# PIC32CX1012BZ25048 device description
Architecture: CORTEX-M4; Family: PIC32CX; Series: BZ25
Registers are 32-bit, read-write, reset 0x0 unless marked. A register's access mark holds for its fields unless they carry their own. Offsets are from the block's base; [hi:lo] are bit positions; {n}, {i} and the like mark numbered series; <NAME> marks a mode.

## DMAC_DESCRIPTOR — Direct Memory Access Controller
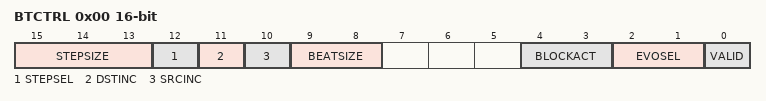
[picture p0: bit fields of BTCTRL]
0x00 BTCTRL 16-bit — Block Transfer Control
  [15:13] STEPSIZE — Address Increment Step Size
    0=Next ADDR = ADDR + (1<<BEATSIZE) * 1; 1=X2 (Next ADDR = ADDR + (1<<BEATSIZE) * 2); 2=X4 (Next ADDR = ADDR + (1<<BEATSIZE) * 4); 3=X8 (Next ADDR = ADDR + (1<<BEATSIZE) * 8); 4=X16 (Next ADDR = ADDR + (1<<BEATSIZE) * 16); 5=X32 (Next ADDR = ADDR + (1<<BEATSIZE) * 32); 6=X64 (Next ADDR = ADDR + (1<<BEATSIZE) * 64); 7=X128 (Next ADDR = ADDR + (1<<BEATSIZE) * 128)
  [12] STEPSEL — Step Selection
    0=DST (Step size settings apply to the destination address); 1=SRC (Step size settings apply to the source address)
  [11] DSTINC — Destination Address Increment Enable
  [10] SRCINC — Source Address Increment Enable
  [9:8] BEATSIZE
    0=BYTE (8-bit bus transfer); 1=HWORD (16-bit bus transfer); 2=WORD (32-bit bus transfer)
  [4:3] BLOCKACT — Block Action
    0=NOACT (Channel will be disabled if it is the last block transfer in the transaction); 1=INT (Channel will be disabled if it is the last block transfer in the transaction and block interrupt); 2=SUSPEND (Channel suspend operation is completed); 3=BOTH (Both channel suspend operation and block interrupt)
  [2:1] EVOSEL — Block Event Output Selection
    0=DISABLE (Event generation disabled); 1=BLOCK (Block event strobe); 3=BURST (Burst event strobe)
  [0] VALID — Descriptor Valid
0x02 BTCNT 16-bit — Block Transfer Count
0x04 SRCADDR — Block Transfer Source Address
  [31:0] SRCADDR — Transfer Source Address
0x08 DSTADDR reset not defined — Block Transfer Destination Address
  [31:0] CHKINIT <CRC> — CRC Checksum Initial Value
  [31:0] DSTADDR <DEFAULT> — Transfer Destination Address
0x0C DESCADDR reset not defined — Next Descriptor Address

## DMT — Dead Man Timer
Instances: DMT 0x44000E00
0x00 DMTCON
  [15] ON
0x04 DMTCONCLR — Bit clear register
0x08 DMTCONSET — Bit set register
0x0C DMTCONINV — Bit invert register
0x10 DMTPRECLR
  [15:8] STEP1
0x14 DMTPRECLRCLR — Bit clear register
0x18 DMTPRECLRSET — Bit set register
0x1C DMTPRECLRINV — Bit invert register
0x20 DMTCLR
  [7:0] STEP2
0x24 DMTCLRCLR — Bit clear register
0x28 DMTCLRSET — Bit set register
0x2C DMTCLRINV — Bit invert register
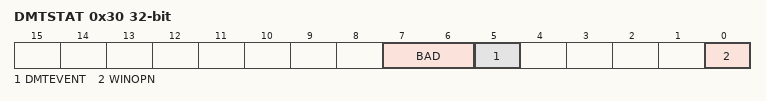
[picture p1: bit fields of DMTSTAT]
0x30 DMTSTAT
  [7:6] BAD, [5] DMTEVENT, [0] WINOPN
0x34 DMTSTATCLR — Bit clear register
0x38 DMTSTATSET — Bit set register
0x3C DMTSTATINV — Bit invert register
0x40 DMTCNT
  [31:0] COUNTER
0x44 DMTCNTCLR — Bit clear register
0x48 DMTCNTSET — Bit set register
0x4C DMTCNTINV — Bit invert register
0x50 DMTHOLDREG
  [15:0] UPRCNT
0x54 DMTHOLDREGCLR — Bit clear register
0x58 DMTHOLDREGSET — Bit set register
0x5C DMTHOLDREGINV — Bit invert register
0x60 DMTPSCNT
  [31:0] PSCNT
0x64 DMTPSCNTCLR — Bit clear register
0x68 DMTPSCNTSET — Bit set register
0x6C DMTPSCNTINV — Bit invert register
0x70 DMTPSINTV
  [31:0] PSINTV
0x74 DMTPSINTVCLR — Bit clear register
0x78 DMTPSINTVSET — Bit set register
0x7C DMTPSINTVINV — Bit invert register

## DSCON
Instances: DSCON 0x42011000
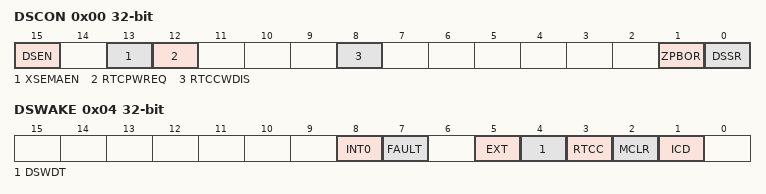
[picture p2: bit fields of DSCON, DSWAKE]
0x00 DSCON
  [15] DSEN, [13] XSEMAEN, [12] RTCPWREQ, [8] RTCCWDIS, [1] ZPBOR, [0] DSSR
0x04 DSWAKE
  [8] INT0, [7] FAULT, [5] EXT, [4] DSWDT, [3] RTCC, [2] MCLR, [1] ICD
0x08 DSSEMA1
  [31:0] DSSEMA
0x10 DSXSEMA1 reset not defined
  [31:0] DSXSEMA

## DSU — Device Service Unit
Instances: DSU 0x41000000
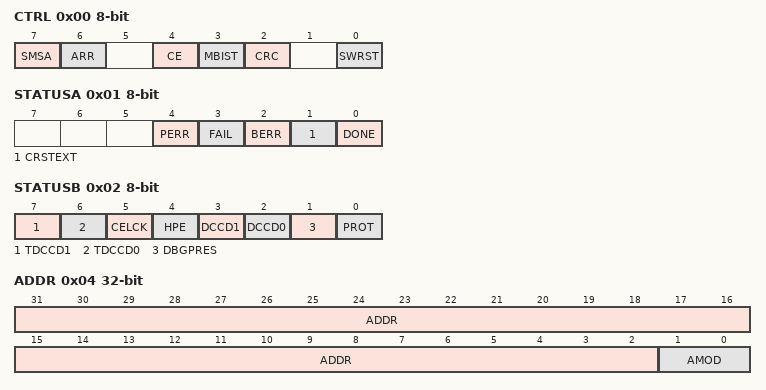
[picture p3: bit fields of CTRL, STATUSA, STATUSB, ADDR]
0x00 CTRL 8-bit wo — Control
  [7] SMSA — Start Memory Stream Access
  [6] ARR — Auxiliary Row Read
  [4] CE — Chip-Erase
  [3] MBIST — Memory built-in self-test
  [2] CRC — 32-bit Cyclic Redundancy Code
  [0] SWRST — Software Reset
0x01 STATUSA 8-bit
  [4] PERR — Protection Error
  [3] FAIL — Failure
  [2] BERR — Bus Error
  [1] CRSTEXT — CPU Reset Phase Extension
  [0] DONE
0x02 STATUSB 8-bit ro
  [7] TDCCD1 — Test Debug Communication Channel 1 Dirty
  [6] TDCCD0 — Test Debug Communication Channel 0 Dirty
  [5] CELCK — Chip Erase Locked
  [4] HPE — Hot-Plugging Enable
  [3] DCCD1 — Debug Communication Channel 1 Dirty
  [2] DCCD0 — Debug Communication Channel 0 Dirty
  [1] DBGPRES — Debugger Present
  [0] PROT — Protected
0x04 ADDR — Address
  [31:2] ADDR — Address
  [1:0] AMOD — Access Mode
0x08 LENGTH
  [31:2] LENGTH
0x0C DATA
{0x10+4i} DCC[{i}] (i=0..1) — Debug Communication Channel n
  [31:0] DATA
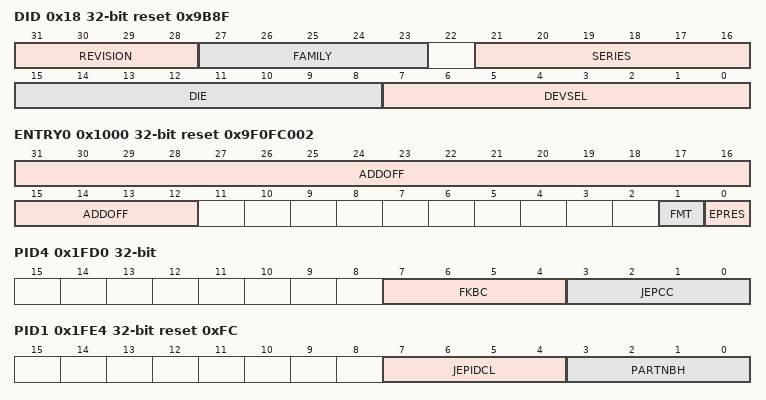
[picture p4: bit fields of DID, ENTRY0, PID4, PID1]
0x18 DID ro reset 0x9B8F — Device Identification
  [31:28] REVISION — Revision Number
  [27:23] FAMILY
    0=General purpose microcontroller; 1=PicoPower
  [21:16] SERIES
    0=Cortex-M0+ processor, basic feature set; 1=Cortex-M0+ processor, USB
  [15:8] DIE — Die Number
  [7:0] DEVSEL — Device Select
0x1000 ENTRY0 ro reset 0x9F0FC002 — CoreSight ROM Table Entry 0
  [31:12] ADDOFF — Address Offset
  [1] FMT — Format
  [0] EPRES — Entry Present
0x1004 ENTRY1 ro — CoreSight ROM Table Entry 1
0x1008 END ro — CoreSight ROM Table End
  [31:0] END — End Marker
0x1FCC MEMTYPE ro — CoreSight ROM Table Memory Type
  [0] SMEMP — System Memory Present
0x1FD0 PID4 ro — Peripheral Identification 4
  [7:4] FKBC — 4KB count
  [3:0] JEPCC — JEP-106 Continuation Code
0x1FE0 PID0 ro reset 0xD0 — Peripheral Identification 0
  [7:0] PARTNBL — Part Number Low
0x1FE4 PID1 ro reset 0xFC — Peripheral Identification 1
  [7:4] JEPIDCL — Low part of the JEP-106 Identity Code
  [3:0] PARTNBH — Part Number High
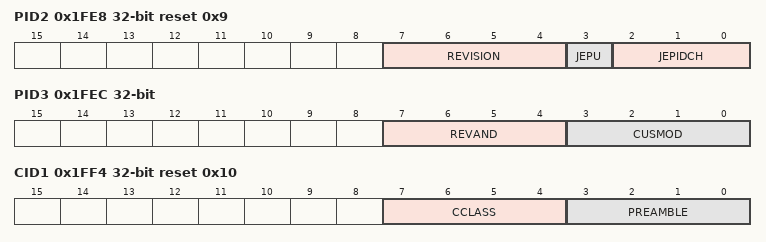
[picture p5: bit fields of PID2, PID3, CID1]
0x1FE8 PID2 ro reset 0x9 — Peripheral Identification 2
  [7:4] REVISION — Revision Number
  [3] JEPU — JEP-106 Identity Code is used
  [2:0] JEPIDCH — JEP-106 Identity Code High
0x1FEC PID3 ro — Peripheral Identification 3
  [7:4] REVAND — Revision Number
  [3:0] CUSMOD — ARM CUSMOD
0x1FF0 CID0 ro reset 0xD — Component Identification 0
  [7:0] PREAMBLEB0 — Preamble Byte 0
0x1FF4 CID1 ro reset 0x10 — Component Identification 1
  [7:4] CCLASS — Component Class
  [3:0] PREAMBLE
0x1FF8 CID2 ro reset 0x5 — Component Identification 2
  [7:0] PREAMBLEB2 — Preamble Byte 2
0x1FFC CID3 ro reset 0xB1 — Component Identification 3
  [7:0] PREAMBLEB3 — Preamble Byte 3
Value list DSU_DID__PROCESSOR: 1=CM0P (Cortex-M0+); 2=CM23 (Cortex-M23); 3=CM3 (Cortex-M3); 5=CM4 (Cortex-M4); 6=CM4F (Cortex-M4 with FPU); 7=CM33 (Cortex-M33)
Value list DSU_CFG__DCCDMALEVEL: 0=EMPTY (Trigger rises when DCC is empty); 1=FULL (Trigger rises when DCC is full)
